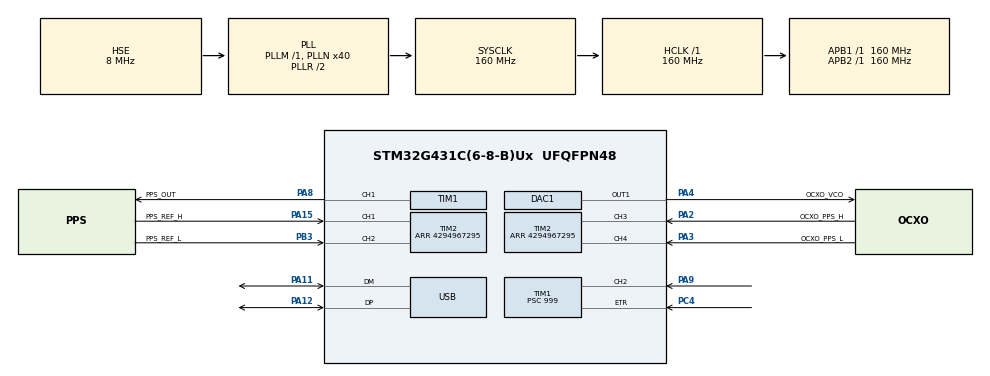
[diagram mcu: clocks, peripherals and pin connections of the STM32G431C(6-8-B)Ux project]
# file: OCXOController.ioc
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Mcu.Family=STM32G4
Mcu.Name=STM32G431C(6-8-B)Ux
Mcu.Package=UFQFPN48
NVIC.PriorityGroup=NVIC_PRIORITYGROUP_4
NVIC.TIM2_IRQn=true\:0\:0\:false\:false\:true\:true\:true\:true
NVIC.USB_LP_IRQn=true\:0\:0\:false\:false\:true\:false\:true\:true
PA11.Mode=Device
PA11.Signal=USB_DM
PA12.Mode=Device
PA12.Signal=USB_DP
PA15.GPIO_Label=PPS_REF_H
PA15.GPIO_Speed=GPIO_SPEED_FREQ_VERY_HIGH
PA15.Signal=S_TIM2_CH1
PA2.GPIO_Label=OCXO_PPS_H
PA2.GPIO_Speed=GPIO_SPEED_FREQ_VERY_HIGH
PA2.Signal=S_TIM2_CH3
PA3.GPIO_Label=OCXO_PPS_L
PA3.GPIO_Speed=GPIO_SPEED_FREQ_VERY_HIGH
PA3.Signal=S_TIM2_CH4
PA4.GPIO_Label=OCXO_VCO
PA4.Signal=COMP_DAC11_group
PA8.GPIO_Label=PPS_OUT
PA8.Signal=S_TIM1_CH1
PA9.Signal=S_TIM1_CH2
PB3.GPIO_Label=PPS_REF_L
PB3.GPIO_Speed=GPIO_SPEED_FREQ_VERY_HIGH
PB3.Signal=S_TIM2_CH2
PC4.Signal=S_TIM1_ETR
PF0-OSC_IN.Mode=HSE-External-Oscillator
PF0-OSC_IN.Signal=RCC_OSC_IN
PF1-OSC_OUT.Mode=HSE-External-Oscillator
PF1-OSC_OUT.Signal=RCC_OSC_OUT
ProjectManager.HeapSize=0x200
ProjectManager.StackSize=0x400
ProjectManager.TargetToolchain=STM32CubeIDE
RCC.ADC12Freq_Value=160000000
RCC.AHBFreq_Value=160000000
RCC.APB1Freq_Value=160000000
RCC.APB1TimFreq_Value=160000000
RCC.APB2Freq_Value=160000000
RCC.APB2TimFreq_Value=160000000
RCC.CK48CLockSelection=RCC_USBCLKSOURCE_HSI48
RCC.CortexFreq_Value=160000000
RCC.EXTERNAL_CLOCK_VALUE=12288000
RCC.HCLKFreq_Value=160000000
RCC.HSE_VALUE=8000000
RCC.HSI48_VALUE=48000000
RCC.HSI_VALUE=16000000
RCC.LSE_VALUE=32768
RCC.PLLN=40
RCC.PLLQ=RCC_PLLQ_DIV4
RCC.PLLSourceVirtual=RCC_PLLSOURCE_HSE
RCC.SYSCLKFreq_VALUE=160000000
RCC.SYSCLKSource=RCC_SYSCLKSOURCE_PLLCLK
RCC.USBFreq_Value=48000000
RCC.VCOOutputFreq_Value=320000000
SH.COMP_DAC11_group.0=DAC1_OUT1,DAC_OUT1
SH.S_TIM1_CH1.0=TIM1_CH1,Output Compare1 CH1
SH.S_TIM1_CH2.0=TIM1_CH2,TriggerSource_TI2FP2
SH.S_TIM1_ETR.0=TIM1_ETR,ClockSourceETR_Mode2
SH.S_TIM2_CH1.0=TIM2_CH1,Input_Capture1_from_TI1
SH.S_TIM2_CH2.0=TIM2_CH2,Input_Capture2_from_TI2
SH.S_TIM2_CH3.0=TIM2_CH3,Input_Capture3_from_TI3
SH.S_TIM2_CH4.0=TIM2_CH4,Input_Capture4_from_TI4
TIM1.Channel-Output\ Compare1\ CH1=TIM_CHANNEL_1
TIM1.OCIdleState_1=TIM_OCIDLESTATE_RESET
TIM1.OCMode_1=TIM_OCMODE_TOGGLE
TIM1.PeriodNoDither=4999
TIM1.Prescaler=999
TIM1.Slave_TriggerPolarity=TIM_TRIGGERPOLARITY_FALLING
TIM2.Channel-Input_Capture1_from_TI1=TIM_CHANNEL_1
TIM2.Channel-Input_Capture2_from_TI2=TIM_CHANNEL_2
TIM2.Channel-Input_Capture3_from_TI3=TIM_CHANNEL_3
TIM2.Channel-Input_Capture4_from_TI4=TIM_CHANNEL_4
TIM2.ICPolarity_CH2=TIM_INPUTCHANNELPOLARITY_FALLING
TIM2.ICPolarity_CH4=TIM_INPUTCHANNELPOLARITY_FALLING
TIM2.PeriodNoDither=4294967295
USB_DEVICE.CLASS_NAME_FS=CDC
USB_DEVICE.VirtualMode=Cdc
USB_DEVICE.VirtualModeFS=Cdc_FS
VP_SYS_VS_DBSignals.Mode=DisableDeadBatterySignals
VP_TIM1_VS_ControllerModeTrigger.Mode=Trigger Mode
VP_TIM2_VS_ClockSourceINT.Mode=Internal
VP_USB_DEVICE_VS_USB_DEVICE_CDC_FS.Mode=CDC_FS
board=custom

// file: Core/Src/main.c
/* USER CODE BEGIN Header */
/**
  ******************************************************************************
  * @file           : main.c
  * @brief          : Main program body
  ******************************************************************************
  * @attention
  *
  * Copyright (c) 2025 STMicroelectronics.
  * All rights reserved.
  *
  * This software is licensed under terms that can be found in the LICENSE file
  * in the root directory of this software component.
  * If no LICENSE file comes with this software, it is provided AS-IS.
  *
  ******************************************************************************
  */
/* USER CODE END Header */
#include "main.h"
#include "usb_device.h"

/* USER CODE BEGIN Includes */
#include "MainMCU.h"
/* USER CODE END Includes */

DAC_HandleTypeDef hdac1;

TIM_HandleTypeDef htim1;
TIM_HandleTypeDef htim2;

void SystemClock_Config(void);
static void MX_GPIO_Init(void);
static void MX_TIM2_Init(void);
static void MX_TIM1_Init(void);
static void MX_DAC1_Init(void);

int main(void)
{

  /* MCU Configuration--------------------------------------------------------*/

  /* Reset of all peripherals, Initializes the Flash interface and the Systick. */
  HAL_Init();

  /* Configure the system clock */
  SystemClock_Config();

  /* Initialize all configured peripherals */
  MX_GPIO_Init();
  MX_TIM2_Init();
  MX_TIM1_Init();
  MX_DAC1_Init();
  MX_USB_Device_Init();
  /* USER CODE BEGIN 2 */
  mcuStart(&hdac1, &htim1, &htim2);
  /* USER CODE END 2 */

  /* Infinite loop */
  while (1)
  {

    /* USER CODE BEGIN 3 */
    mcuLoop();
  }
  /* USER CODE END 3 */
}

void SystemClock_Config(void)
{
  RCC_OscInitTypeDef RCC_OscInitStruct = {0};
  RCC_ClkInitTypeDef RCC_ClkInitStruct = {0};

  /** Configure the main internal regulator output voltage
  */
  HAL_PWREx_ControlVoltageScaling(PWR_REGULATOR_VOLTAGE_SCALE1_BOOST);

  /** Initializes the RCC Oscillators according to the specified parameters
  * in the RCC_OscInitTypeDef structure.
  */
  RCC_OscInitStruct.OscillatorType = RCC_OSCILLATORTYPE_HSI48|RCC_OSCILLATORTYPE_HSE;
  RCC_OscInitStruct.HSEState = RCC_HSE_ON;
  RCC_OscInitStruct.HSI48State = RCC_HSI48_ON;
  RCC_OscInitStruct.PLL.PLLState = RCC_PLL_ON;
  RCC_OscInitStruct.PLL.PLLSource = RCC_PLLSOURCE_HSE;
  RCC_OscInitStruct.PLL.PLLM = RCC_PLLM_DIV1;
  RCC_OscInitStruct.PLL.PLLN = 40;
  RCC_OscInitStruct.PLL.PLLP = RCC_PLLP_DIV2;
  RCC_OscInitStruct.PLL.PLLQ = RCC_PLLQ_DIV4;
  RCC_OscInitStruct.PLL.PLLR = RCC_PLLR_DIV2;
  if (HAL_RCC_OscConfig(&RCC_OscInitStruct) != HAL_OK)
  {
    Error_Handler();
  }

  /** Initializes the CPU, AHB and APB buses clocks
  */
  RCC_ClkInitStruct.ClockType = RCC_CLOCKTYPE_HCLK|RCC_CLOCKTYPE_SYSCLK
                              |RCC_CLOCKTYPE_PCLK1|RCC_CLOCKTYPE_PCLK2;
  RCC_ClkInitStruct.SYSCLKSource = RCC_SYSCLKSOURCE_PLLCLK;
  RCC_ClkInitStruct.AHBCLKDivider = RCC_SYSCLK_DIV1;
  RCC_ClkInitStruct.APB1CLKDivider = RCC_HCLK_DIV1;
  RCC_ClkInitStruct.APB2CLKDivider = RCC_HCLK_DIV1;

  if (HAL_RCC_ClockConfig(&RCC_ClkInitStruct, FLASH_LATENCY_4) != HAL_OK)
  {
    Error_Handler();
  }
}

static void MX_DAC1_Init(void)
{

  DAC_ChannelConfTypeDef sConfig = {0};

  /** DAC Initialization
  */
  hdac1.Instance = DAC1;
  if (HAL_DAC_Init(&hdac1) != HAL_OK)
  {
    Error_Handler();
  }

  /** DAC channel OUT1 config
  */
  sConfig.DAC_HighFrequency = DAC_HIGH_FREQUENCY_INTERFACE_MODE_AUTOMATIC;
  sConfig.DAC_DMADoubleDataMode = DISABLE;
  sConfig.DAC_SignedFormat = DISABLE;
  sConfig.DAC_SampleAndHold = DAC_SAMPLEANDHOLD_DISABLE;
  sConfig.DAC_Trigger = DAC_TRIGGER_NONE;
  sConfig.DAC_Trigger2 = DAC_TRIGGER_NONE;
  sConfig.DAC_OutputBuffer = DAC_OUTPUTBUFFER_ENABLE;
  sConfig.DAC_ConnectOnChipPeripheral = DAC_CHIPCONNECT_EXTERNAL;
  sConfig.DAC_UserTrimming = DAC_TRIMMING_FACTORY;
  if (HAL_DAC_ConfigChannel(&hdac1, &sConfig, DAC_CHANNEL_1) != HAL_OK)
  {
    Error_Handler();
  }

}

static void MX_TIM1_Init(void)
{

  TIM_ClockConfigTypeDef sClockSourceConfig = {0};
  TIM_MasterConfigTypeDef sMasterConfig = {0};
  TIM_OC_InitTypeDef sConfigOC = {0};
  TIM_BreakDeadTimeConfigTypeDef sBreakDeadTimeConfig = {0};

  htim1.Instance = TIM1;
  htim1.Init.Prescaler = 999;
  htim1.Init.CounterMode = TIM_COUNTERMODE_UP;
  htim1.Init.Period = 4999;
  htim1.Init.ClockDivision = TIM_CLOCKDIVISION_DIV1;
  htim1.Init.RepetitionCounter = 0;
  htim1.Init.AutoReloadPreload = TIM_AUTORELOAD_PRELOAD_DISABLE;
  if (HAL_TIM_Base_Init(&htim1) != HAL_OK)
  {
    Error_Handler();
  }
  sClockSourceConfig.ClockSource = TIM_CLOCKSOURCE_ETRMODE2;
  sClockSourceConfig.ClockPolarity = TIM_CLOCKPOLARITY_NONINVERTED;
  sClockSourceConfig.ClockPrescaler = TIM_CLOCKPRESCALER_DIV1;
  sClockSourceConfig.ClockFilter = 0;
  if (HAL_TIM_ConfigClockSource(&htim1, &sClockSourceConfig) != HAL_OK)
  {
    Error_Handler();
  }
  if (HAL_TIM_OC_Init(&htim1) != HAL_OK)
  {
    Error_Handler();
  }
  sMasterConfig.MasterOutputTrigger = TIM_TRGO_RESET;
  sMasterConfig.MasterOutputTrigger2 = TIM_TRGO2_RESET;
  sMasterConfig.MasterSlaveMode = TIM_MASTERSLAVEMODE_DISABLE;
  if (HAL_TIMEx_MasterConfigSynchronization(&htim1, &sMasterConfig) != HAL_OK)
  {
    Error_Handler();
  }
  sConfigOC.OCMode = TIM_OCMODE_TOGGLE;
  sConfigOC.Pulse = 0;
  sConfigOC.OCPolarity = TIM_OCPOLARITY_HIGH;
  sConfigOC.OCNPolarity = TIM_OCNPOLARITY_HIGH;
  sConfigOC.OCFastMode = TIM_OCFAST_DISABLE;
  sConfigOC.OCIdleState = TIM_OCIDLESTATE_RESET;
  sConfigOC.OCNIdleState = TIM_OCNIDLESTATE_RESET;
  if (HAL_TIM_OC_ConfigChannel(&htim1, &sConfigOC, TIM_CHANNEL_1) != HAL_OK)
  {
    Error_Handler();
  }
  sBreakDeadTimeConfig.OffStateRunMode = TIM_OSSR_DISABLE;
  sBreakDeadTimeConfig.OffStateIDLEMode = TIM_OSSI_DISABLE;
  sBreakDeadTimeConfig.LockLevel = TIM_LOCKLEVEL_OFF;
  sBreakDeadTimeConfig.DeadTime = 0;
  sBreakDeadTimeConfig.BreakState = TIM_BREAK_DISABLE;
  sBreakDeadTimeConfig.BreakPolarity = TIM_BREAKPOLARITY_HIGH;
  sBreakDeadTimeConfig.BreakFilter = 0;
  sBreakDeadTimeConfig.BreakAFMode = TIM_BREAK_AFMODE_INPUT;
  sBreakDeadTimeConfig.Break2State = TIM_BREAK2_DISABLE;
  sBreakDeadTimeConfig.Break2Polarity = TIM_BREAK2POLARITY_HIGH;
  sBreakDeadTimeConfig.Break2Filter = 0;
  sBreakDeadTimeConfig.Break2AFMode = TIM_BREAK_AFMODE_INPUT;
  sBreakDeadTimeConfig.AutomaticOutput = TIM_AUTOMATICOUTPUT_DISABLE;
  if (HAL_TIMEx_ConfigBreakDeadTime(&htim1, &sBreakDeadTimeConfig) != HAL_OK)
  {
    Error_Handler();
  }
  HAL_TIM_MspPostInit(&htim1);

}

static void MX_TIM2_Init(void)
{

  TIM_ClockConfigTypeDef sClockSourceConfig = {0};
  TIM_MasterConfigTypeDef sMasterConfig = {0};
  TIM_IC_InitTypeDef sConfigIC = {0};

  htim2.Instance = TIM2;
  htim2.Init.Prescaler = 0;
  htim2.Init.CounterMode = TIM_COUNTERMODE_UP;
  htim2.Init.Period = 4294967295;
  htim2.Init.ClockDivision = TIM_CLOCKDIVISION_DIV1;
  htim2.Init.AutoReloadPreload = TIM_AUTORELOAD_PRELOAD_DISABLE;
  if (HAL_TIM_Base_Init(&htim2) != HAL_OK)
  {
    Error_Handler();
  }
  sClockSourceConfig.ClockSource = TIM_CLOCKSOURCE_INTERNAL;
  if (HAL_TIM_ConfigClockSource(&htim2, &sClockSourceConfig) != HAL_OK)
  {
    Error_Handler();
  }
  if (HAL_TIM_IC_Init(&htim2) != HAL_OK)
  {
    Error_Handler();
  }
  sMasterConfig.MasterOutputTrigger = TIM_TRGO_RESET;
  sMasterConfig.MasterSlaveMode = TIM_MASTERSLAVEMODE_DISABLE;
  if (HAL_TIMEx_MasterConfigSynchronization(&htim2, &sMasterConfig) != HAL_OK)
  {
    Error_Handler();
  }
  sConfigIC.ICPolarity = TIM_INPUTCHANNELPOLARITY_RISING;
  sConfigIC.ICSelection = TIM_ICSELECTION_DIRECTTI;
  sConfigIC.ICPrescaler = TIM_ICPSC_DIV1;
  sConfigIC.ICFilter = 0;
  if (HAL_TIM_IC_ConfigChannel(&htim2, &sConfigIC, TIM_CHANNEL_1) != HAL_OK)
  {
    Error_Handler();
  }
  sConfigIC.ICPolarity = TIM_INPUTCHANNELPOLARITY_FALLING;
  if (HAL_TIM_IC_ConfigChannel(&htim2, &sConfigIC, TIM_CHANNEL_2) != HAL_OK)
  {
    Error_Handler();
  }
  sConfigIC.ICPolarity = TIM_INPUTCHANNELPOLARITY_RISING;
  if (HAL_TIM_IC_ConfigChannel(&htim2, &sConfigIC, TIM_CHANNEL_3) != HAL_OK)
  {
    Error_Handler();
  }
  sConfigIC.ICPolarity = TIM_INPUTCHANNELPOLARITY_FALLING;
  if (HAL_TIM_IC_ConfigChannel(&htim2, &sConfigIC, TIM_CHANNEL_4) != HAL_OK)
  {
    Error_Handler();
  }

}

static void MX_GPIO_Init(void)
{

  /* GPIO Ports Clock Enable */
  __HAL_RCC_GPIOF_CLK_ENABLE();
  __HAL_RCC_GPIOA_CLK_ENABLE();
  __HAL_RCC_GPIOC_CLK_ENABLE();
  __HAL_RCC_GPIOB_CLK_ENABLE();

}

void Error_Handler(void)
{
  __disable_irq();
  while (1)
  {
  }
}
